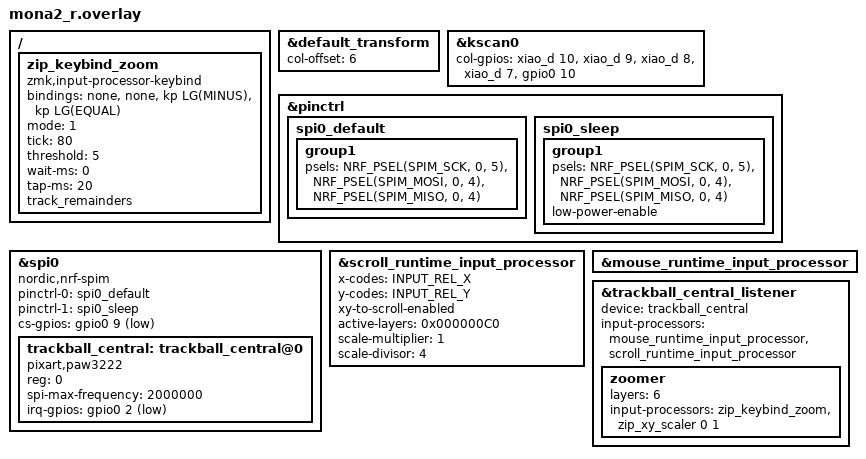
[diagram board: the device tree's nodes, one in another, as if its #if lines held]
#include "mona2.dtsi"
/* mona2.dtsi 内で RC(row,col) のマトリクス展開が終わった後に include する
   (runtime-input-processor.dtsi が modifiers.h 経由で RC(keycode) を再定義するため) */
#include <input/processors/runtime-input-processor.dtsi>
#include <input/processors.dtsi>
#include <zephyr/dt-bindings/input/input-event-codes.h>
#include <behaviors.dtsi>
#include <dt-bindings/zmk/keys.h>


/ {
    // トラックボール Y 軸を ⌘=/⌘- に離散化してズームを実現する
    //   mode=1   : 4 方向（X/Y いずれか強い方だけ発火）
    //   tick=80  : 80 カウント分動かすと 1 回発火（暴発防止のため少し鈍めに）
    //   threshold=5 : これ未満の微小移動は無視
    zip_keybind_zoom: zip_keybind_zoom {
        compatible = "zmk,input-processor-keybind";
        #input-processor-cells = <0>;
        bindings =
            <&none>,            // X+ (右): 未使用
            <&none>,            // X- (左): 未使用
            <&kp LG(MINUS)>,    // Y+ : ズームアウト
            <&kp LG(EQUAL)>;    // Y- : ズームイン
        mode = <1>;
        tick = <80>;
        threshold = <5>;
        wait-ms = <0>;
        tap-ms = <20>;
        track_remainders;
    };
};

&default_transform {
    col-offset = <6>;
};

&kscan0 {
    col-gpios
        = <&xiao_d 10 GPIO_ACTIVE_HIGH>
        , <&xiao_d 9 GPIO_ACTIVE_HIGH>
        , <&xiao_d 8 GPIO_ACTIVE_HIGH>
        , <&xiao_d 7 GPIO_ACTIVE_HIGH>
        , <&gpio0 10 GPIO_ACTIVE_HIGH>
        ;
};

&pinctrl {
    spi0_default: spi0_default {
        group1 {
            psels = <NRF_PSEL(SPIM_SCK, 0, 5)>,
                    <NRF_PSEL(SPIM_MOSI, 0, 4)>,
                    <NRF_PSEL(SPIM_MISO, 0, 4)>;
        };
    };

    spi0_sleep: spi0_sleep {
        group1 {
            psels = <NRF_PSEL(SPIM_SCK, 0, 5)>,
                    <NRF_PSEL(SPIM_MOSI, 0, 4)>,
                    <NRF_PSEL(SPIM_MISO, 0, 4)>;
            low-power-enable;
        };
    };
};

&spi0 {
    status = "okay";
    compatible = "nordic,nrf-spim";
    pinctrl-0 = <&spi0_default>;
    pinctrl-1 = <&spi0_sleep>;
    pinctrl-names = "default", "sleep";
    cs-gpios = <&gpio0 9 GPIO_ACTIVE_LOW>;

    trackball_central: trackball_central@0 {
        status = "okay";
#ifdef CONFIG_TRACKBALL_PAW3222
        compatible = "pixart,paw3222";
        reg = <0>;
        spi-max-frequency = <2000000>;
        irq-gpios = <&gpio0 2 (GPIO_ACTIVE_LOW | GPIO_PULL_UP)>;
#else /* default: PMW3610 */
        compatible = "pixart,pmw3610";
        reg = <0>;
        spi-max-frequency = <2000000>;
        irq-gpios = <&gpio0 2 (GPIO_ACTIVE_LOW | GPIO_PULL_UP)>;
        cpi = <600>;
        //swap-xy;
        invert-x; //COROPIT版ではコメントアウトを外す
        invert-y; //COROPIT版ではコメントアウトを外す
        evt-type = <INPUT_EV_REL>;
        x-input-code = <INPUT_REL_X>;
        y-input-code = <INPUT_REL_Y>;
#endif
    };
};

/* ─────────────────────────────────────────────────────────────
   scroll_runtime_input_processor をスクロール変換器として上書き

   デフォルトでは x-codes=HWHEEL / y-codes=WHEEL で
   「すでにスクロールイベントになっているもの」しか処理しない設定。
   トラックボールの生イベント(REL_X/Y) を受け取って
   xy-to-scroll-enabled でスクロールに変換する形に切替える。

   ・active-layers : デフォルトのスクロールレイヤー bitmask
                     bit6=scroll_win, bit7=scroll_mac → 0x000000C0
                     DYA Studio から変更可能(再ビルド不要)
   ・xy-to-scroll-enabled : REL_X→HWHEEL, REL_Y→WHEEL に変換
                            こちらも Studio から ON/OFF 可能
   ────────────────────────────────────────────────────── */
&scroll_runtime_input_processor {
    x-codes = <INPUT_REL_X>;
    y-codes = <INPUT_REL_Y>;
    xy-to-scroll-enabled;
    active-layers = <0x000000C0>;  /* layer6 + layer7 */
    scale-multiplier = <1>;
    scale-divisor = <4>;            /* スクロール速度。大きいほど遅い。Studioで調整可 */
    /* 軸ロック(縦のみ等)が欲しければ AXIS_SNAP_MODE_Y を初期値に */
    /* #include <dt-bindings/zmk/runtime_input_processor.h> 必要 */
    /* axis-snap-mode = <2>; */
    /* axis-snap-threshold = <100>; */
};

/* マウス用は全レイヤーで有効 (active-layers = 0 がデフォルト) */
&mouse_runtime_input_processor {
    /* 例: マウス感度初期値を Studio から調整したいだけならここで触らなくてOK */
};

/* ─────────────────────────────────────────────────────────────
   入力リスナー
   メインチェーンに mouse → scroll の順で2段。
   ・mouse は全レイヤーで走る(scale/invert を適用)
   ・scroll は active-layers のレイヤーでのみ走る
     → 該当レイヤー以外では素通しでマウスとして動作
   scroller {} 子ノードは使わない(レイヤー固定になるため)
   ────────────────────────────────────────────────────── */
&trackball_central_listener {
    status = "okay";
    device = <&trackball_central>;
    input-processors = <&mouse_runtime_input_processor &scroll_runtime_input_processor>;

    // Layer 6 (/-hold): トラックボール上下でズームイン/アウト
    //   zip_keybind_zoom で Y 軸の移動量を ⌘= / ⌘- に変換
    //   zip_xy_scaler 0 1 で XY を無効化してポインタが動かないようにする（本家ZMK使用時のワークアラウンド）
    zoomer {
        layers = <6>;
        input-processors =
            <&zip_keybind_zoom>,
            <&zip_xy_scaler 0 1>;
    };
};
